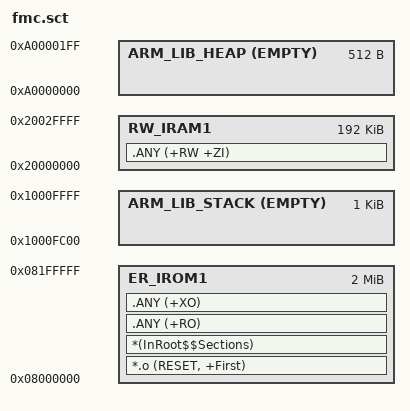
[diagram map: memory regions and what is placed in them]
; *************************************************************
; *** Scatter-Loading Description File generated by uVision ***
; *************************************************************
#define FMC_R_BASE            0xA0000000UL /*!< FMC registers base address                                                 */
#define SRAM1_BB_BASE         0x22000000UL /*!< SRAM1(112 KB) base address in the bit-band region                          */
#define SRAM2_BB_BASE         0x22380000UL /*!< SRAM2(16 KB) base address in the bit-band region                           */
#define SRAM3_BB_BASE         0x22400000UL /*!< SRAM3(64 KB) base address in the bit-band region                           */
#define FMC_Bank5_6_R_BASE    (FMC_R_BASE + 0x0140UL)

LR_IROM1 0x08000000 0x00200000  {    ; load region size_region
  ER_IROM1 0x08000000 0x00200000  {  ; load address = execution address
   *.o (RESET, +First)
   *(InRoot$$Sections)
   .ANY (+RO)
   .ANY (+XO)
  }
  RW_IRAM1 0x20000000 0x00030000  {  ; RW data
   .ANY (+RW +ZI)
  }
  /*RW_IRAM2 0x10000000 0x00010000  {
   .ANY (+RW +ZI)
  }*/
  ARM_LIB_STACK 0x10010000 EMPTY -0x0400 {
  }
  ARM_LIB_HEAP 0xA0000000 EMPTY 0x0200 {
  }
}

